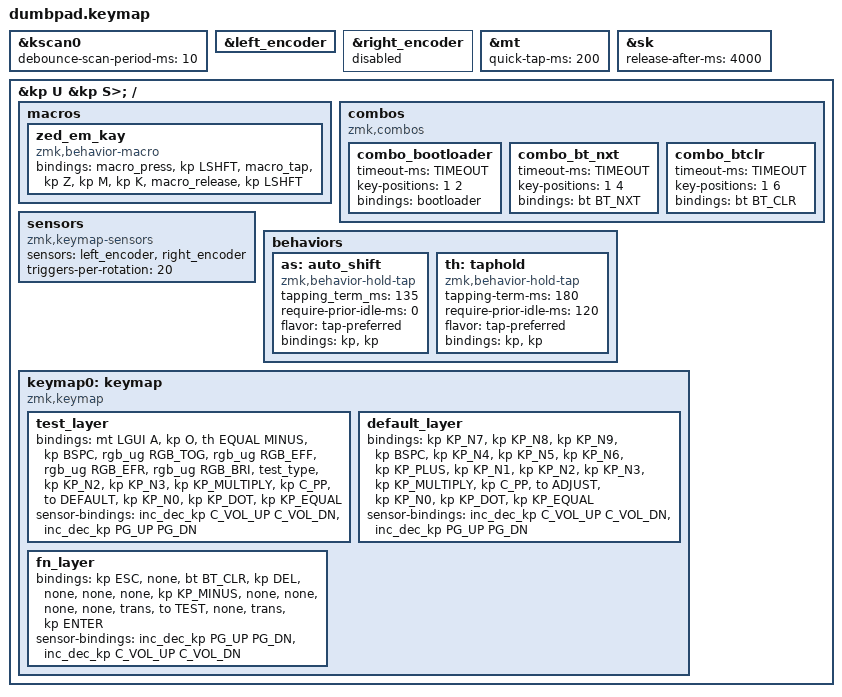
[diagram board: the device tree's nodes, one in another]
/*
 * Copyright (c) 2022 The ZMK Contributors
 *
 * SPDX-License-Identifier: MIT
 */

#include <behaviors.dtsi>
#include <dt-bindings/zmk/keys.h>
#include <dt-bindings/zmk/bt.h>
#include <dt-bindings/zmk/ext_power.h>
#include <dt-bindings/zmk/mouse.h>
#include <behaviors/mouse_key_press.dtsi>

#include <zmk-nodefree-config/helper.h>
#include <zmk-nodefree-config/keypos_def/keypos_36keys.h>

#define TIMEOUT 50

#define TEST 0
#define DEFAULT 1
#define ADJUST  2

&kscan0 {
    debounce-scan-period-ms = <10>;
};
&left_encoder {
    status = "okay";
};

&right_encoder {
    status = "disabled";
};

&mt {
        quick-tap-ms = <200>;
};

&sk {
   	release-after-ms = <4000>;
};

// windows sleep macro
ZMK_BEHAVIOR(win_sleep, macro,
    wait-ms = <100>;
    tap-ms = <5>;
    bindings = <&kp LG(X) &kp U &kp S>;
/*)*/

/ {
/*  ------------------
 *  |     0  1  2  3 |
 *  |     4  5  6  7 |
 *  |     8  9 10 11 |
 *  | 12 13 14 15 16 |
 *  ------------------
 */
    macros {
        zed_em_kay: zed_em_kay {
            compatible = "zmk,behavior-macro";
            #binding-cells = <0>;
            bindings
                = <&macro_press &kp LSHFT>
                , <&macro_tap &kp Z &kp M &kp K>
                , <&macro_release &kp LSHFT>
                ;
        };
    };
    combos {
        compatible = "zmk,combos";
        combo_bootloader {
            timeout-ms = <TIMEOUT>;
            key-positions = <1 2>;
            bindings = <&bootloader>;
        };
        combo_bt_nxt {
            timeout-ms = <TIMEOUT>;
            key-positions = <1 4>;
            bindings = <&bt BT_NXT>;
        };
        combo_btclr {
            timeout-ms = <TIMEOUT>;
            key-positions = <1 6>;
            bindings = <&bt BT_CLR>;
        };
    };

    sensors {
        compatible = "zmk,keymap-sensors";
        sensors = <&left_encoder &right_encoder>;
	triggers-per-rotation = <20>;
    };

    behaviors {

        as: auto_shift {
            compatible = "zmk,behavior-hold-tap";
            #binding-cells = <2>;
            tapping_term_ms = <135>;
            require-prior-idle-ms = <0>;
            flavor = "tap-preferred";
            bindings = <&kp>, <&kp>;
        };
	th: taphold {
            compatible = "zmk,behavior-hold-tap";
            #binding-cells = <2>;
            tapping-term-ms = <180>;
            require-prior-idle-ms = <120>;
            flavor = "tap-preferred";
            bindings = <&kp>, <&kp>;
        };

    };
    keymap0: keymap {
        compatible = "zmk,keymap";

        test_layer {
            bindings = <
                            &mt LGUI A	&kp O	&th EQUAL MINUS	&kp BSPC
                            &rgb_ug RGB_TOG    &rgb_ug RGB_EFF    &rgb_ug RGB_EFR    &rgb_ug RGB_BRI
                            &test_type    &kp KP_N2       &kp KP_N3         &kp KP_MULTIPLY
                &kp C_PP    &to DEFAULT   &kp KP_N0       &kp KP_DOT        &kp KP_EQUAL
            >;
            sensor-bindings = <&inc_dec_kp C_VOL_UP C_VOL_DN &inc_dec_kp PG_UP PG_DN>;

        };

        default_layer {
            
            bindings = <
                            &kp KP_N7    &kp KP_N8       &kp KP_N9         &kp BSPC
                            &kp KP_N4    &kp KP_N5       &kp KP_N6         &kp KP_PLUS
                            &kp KP_N1    &kp KP_N2       &kp KP_N3         &kp KP_MULTIPLY
                &kp C_PP    &to ADJUST   &kp KP_N0       &kp KP_DOT        &kp KP_EQUAL
            >;
            sensor-bindings = <&inc_dec_kp C_VOL_UP C_VOL_DN &inc_dec_kp PG_UP PG_DN>;

        };

        fn_layer {
            
            bindings = <
                            &kp ESC    &none         &bt BT_CLR      &kp DEL
                            &none      &none         &none           &kp KP_MINUS
                            &none	&none	&none	&none
                &trans      &to TEST     &none         &trans          &kp ENTER
            >;
            sensor-bindings = <&inc_dec_kp PG_UP PG_DN &inc_dec_kp C_VOL_UP C_VOL_DN>;
        };
    };
};
